AUTOSAR XML (schema 4-0-3)
package /ComponentTypes
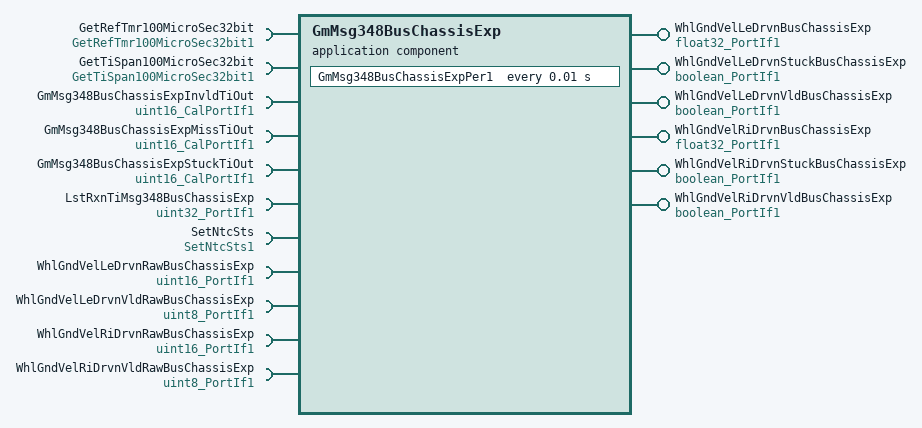
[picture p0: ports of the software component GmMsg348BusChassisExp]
  application sw component type GmMsg348BusChassisExp
    6 x provide port:
      WhlGndVelLeDrvnBusChassisExp: nonqueued-sender-com-spec{data-element=Val, init-value=0}, provided-interface=float32_PortIf1
      WhlGndVelLeDrvnStuckBusChassisExp: nonqueued-sender-com-spec{data-element=Logl, init-value=0}, provided-interface=boolean_PortIf1
      WhlGndVelLeDrvnVldBusChassisExp: nonqueued-sender-com-spec{data-element=Logl, init-value=0}, provided-interface=boolean_PortIf1
      WhlGndVelRiDrvnBusChassisExp: nonqueued-sender-com-spec{data-element=Val, init-value=0}, provided-interface=float32_PortIf1
      WhlGndVelRiDrvnStuckBusChassisExp: nonqueued-sender-com-spec{data-element=Logl, init-value=0}, provided-interface=boolean_PortIf1
      WhlGndVelRiDrvnVldBusChassisExp: nonqueued-sender-com-spec{data-element=Logl, init-value=0}, provided-interface=boolean_PortIf1
    11 x require port:
      GetRefTmr100MicroSec32bit: required-interface=GetRefTmr100MicroSec32bit1
      GetTiSpan100MicroSec32bit: required-interface=GetTiSpan100MicroSec32bit1
      GmMsg348BusChassisExpInvldTiOut: parameter-require-com-spec{init-value=1000, parameter=Val}, required-interface=uint16_CalPortIf1
      GmMsg348BusChassisExpMissTiOut: parameter-require-com-spec{init-value=500, parameter=Val}, required-interface=uint16_CalPortIf1
      GmMsg348BusChassisExpStuckTiOut: parameter-require-com-spec{init-value=500, parameter=Val}, required-interface=uint16_CalPortIf1
      LstRxnTiMsg348BusChassisExp: nonqueued-receiver-com-spec{data-element=Val, filter=data-filter-type=ALWAYS, init-value=0}, required-interface=uint32_PortIf1
      SetNtcSts: required-interface=SetNtcSts1
      WhlGndVelLeDrvnRawBusChassisExp: nonqueued-receiver-com-spec{data-element=Val, filter=data-filter-type=ALWAYS, init-value=0}, required-interface=uint16_PortIf1
      WhlGndVelLeDrvnVldRawBusChassisExp: nonqueued-receiver-com-spec{data-element=Val, filter=data-filter-type=ALWAYS, init-value=0}, required-interface=uint8_PortIf1
      WhlGndVelRiDrvnRawBusChassisExp: nonqueued-receiver-com-spec{data-element=Val, filter=data-filter-type=ALWAYS, init-value=0}, required-interface=uint16_PortIf1
      WhlGndVelRiDrvnVldRawBusChassisExp: nonqueued-receiver-com-spec{data-element=Val, filter=data-filter-type=ALWAYS, init-value=0}, required-interface=uint8_PortIf1
    behavior GmMsg348BusChassisExp_InternalBehavior: data-type-mapping=Nexteer
      ar-typed-per-instance-memorys:
        6 x data, all with sw-calibration-access=READ-ONLY:
          GmMsg348BusChassisExpPrevWhlGndVelLeDrvn: type=uint16
          GmMsg348BusChassisExpPrevWhlGndVelRiDrvn: type=uint16
          GmMsg348BusChassisExpWhlGndVelLeDrvnInvldTi: type=uint32
          GmMsg348BusChassisExpWhlGndVelLeDrvnStuckTi: type=uint32
          GmMsg348BusChassisExpWhlGndVelRiDrvnInvldTi: type=uint32
          GmMsg348BusChassisExpWhlGndVelRiDrvnStuckTi: type=uint32
      timing event TMT_GM0C9HSPer1: start-on-event=GmMsg348BusChassisExpPer1, period=0.01
      runnable GmMsg348BusChassisExpPer1
        data-receive-point-by-arguments:
          5 x access:
            REC_HiSpdWhlGndVelLeDrvn_Val: accessed-variable=WhlGndVelLeDrvnRawBusChassisExp.Val
            REC_HiSpdWhlGndVelLeDrvnVld_Val: accessed-variable=WhlGndVelLeDrvnVldRawBusChassisExp.Val
            REC_HiSpdWhlGndVelRiDrvn_Val: accessed-variable=WhlGndVelRiDrvnRawBusChassisExp.Val
            REC_HiSpdWhlGndVelRiDrvnVld_Val: accessed-variable=WhlGndVelRiDrvnVldRawBusChassisExp.Val
            REC_Msg348HSLstRxnTi_Val: accessed-variable=LstRxnTiMsg348BusChassisExp.Val
        data-send-points:
          6 x access:
            SEND_GM348HSWhlGndVelLeDrvn_Val: accessed-variable=WhlGndVelLeDrvnBusChassisExp.Val
            SEND_GM348HSWhlGndVelLeDrvnVld_Logl: accessed-variable=WhlGndVelLeDrvnVldBusChassisExp.Logl
            SEND_GM348HSWhlGndVelRiDrvn_Val: accessed-variable=WhlGndVelRiDrvnBusChassisExp.Val
            SEND_GM348HSWhlGndVelRiDrvnVld_Logl: accessed-variable=WhlGndVelRiDrvnVldBusChassisExp.Logl
            SEND_WhlGndVelLeDrvnStuckBusChassisExp_Logl: accessed-variable=WhlGndVelLeDrvnStuckBusChassisExp.Logl
            SEND_WhlGndVelRiDrvnStuckBusChassisExp_Logl: accessed-variable=WhlGndVelRiDrvnStuckBusChassisExp.Logl
        sync call SC_GetRefTmr100MicroSec32bit_Oper: operation=GetRefTmr100MicroSec32bit.Oper, timeout=0
        sync call SC_GetTiSpan100MicroSec32bit_Oper: operation=GetTiSpan100MicroSec32bit.Oper, timeout=0
        sync call SC_SetNtcSts_Oper: operation=SetNtcSts.Oper, timeout=0
  swc implementation GmMsg348BusChassisExp_Implementation: behavior=GmMsg348BusChassisExp_InternalBehavior
    code-descriptors:
      code Default: artifact-descriptors=autosar-engineering-object={short-label=Default, category=SWSRC}
